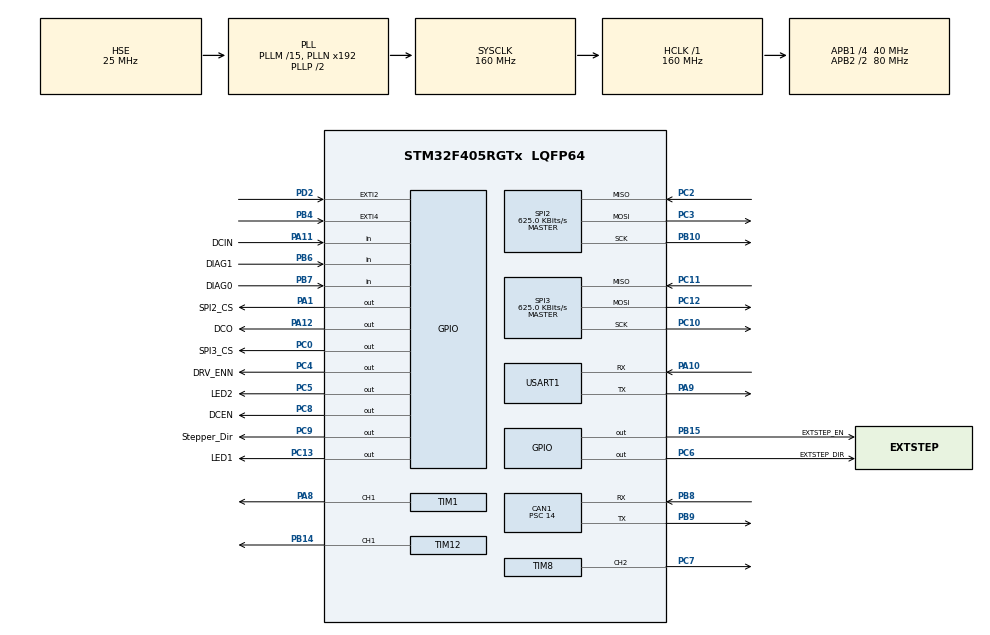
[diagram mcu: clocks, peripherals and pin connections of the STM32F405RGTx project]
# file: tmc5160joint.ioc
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CAN1.BS1=CAN_BS1_10TQ
CAN1.CalculateTimeQuantum=350.0
CAN1.Prescaler=14
Dma.Request0=USART1_RX
Dma.Request1=USART1_TX
Dma.USART1_RX.0.Direction=DMA_PERIPH_TO_MEMORY
Dma.USART1_RX.0.FIFOMode=DMA_FIFOMODE_DISABLE
Dma.USART1_RX.0.Instance=DMA2_Stream2
Dma.USART1_RX.0.MemDataAlignment=DMA_MDATAALIGN_BYTE
Dma.USART1_RX.0.MemInc=DMA_MINC_ENABLE
Dma.USART1_RX.0.Mode=DMA_CIRCULAR
Dma.USART1_RX.0.PeriphDataAlignment=DMA_PDATAALIGN_BYTE
Dma.USART1_RX.0.PeriphInc=DMA_PINC_DISABLE
Dma.USART1_RX.0.Priority=DMA_PRIORITY_LOW
Dma.USART1_TX.1.Direction=DMA_MEMORY_TO_PERIPH
Dma.USART1_TX.1.FIFOMode=DMA_FIFOMODE_DISABLE
Dma.USART1_TX.1.Instance=DMA2_Stream7
Dma.USART1_TX.1.MemDataAlignment=DMA_MDATAALIGN_BYTE
Dma.USART1_TX.1.MemInc=DMA_MINC_ENABLE
Dma.USART1_TX.1.Mode=DMA_NORMAL
Dma.USART1_TX.1.PeriphDataAlignment=DMA_PDATAALIGN_BYTE
Dma.USART1_TX.1.PeriphInc=DMA_PINC_DISABLE
Dma.USART1_TX.1.Priority=DMA_PRIORITY_LOW
FREERTOS.Tasks01=defaultTask,24,256,DefaultTaskMain,Default,NULL,Dynamic,NULL,NULL;ledTask,8,128,LedTaskMain,Default,NULL,Dynamic,NULL,NULL;encoderTask,8,512,EncoderTaskMain,Default,NULL,Dynamic,NULL,NULL;uartTask,8,128,UITaskMain,Default,NULL,Dynamic,NULL,NULL;canTask,8,512,CanCommTaskMain,Default,NULL,Dynamic,NULL,NULL
Mcu.Family=STM32F4
Mcu.Name=STM32F405RGTx
Mcu.Package=LQFP64
NVIC.CAN1_RX0_IRQn=true\:0\:0\:false\:false\:true\:false\:true\:true
NVIC.CAN1_RX1_IRQn=true\:0\:0\:false\:false\:true\:false\:true\:true
NVIC.CAN1_SCE_IRQn=true\:0\:0\:false\:false\:true\:false\:true\:true
NVIC.CAN1_TX_IRQn=true\:0\:0\:false\:false\:true\:false\:true\:true
NVIC.DMA2_Stream2_IRQn=true\:0\:0\:false\:false\:true\:true\:false\:true
NVIC.DMA2_Stream7_IRQn=true\:0\:0\:false\:false\:true\:true\:false\:true
NVIC.EXTI2_IRQn=true\:0\:0\:false\:false\:true\:false\:true\:true
NVIC.PriorityGroup=NVIC_PRIORITYGROUP_4
NVIC.TIM1_CC_IRQn=true\:0\:0\:false\:false\:true\:false\:true\:true
NVIC.TIM1_UP_TIM10_IRQn=true\:0\:0\:false\:false\:true\:false\:true\:true
NVIC.TIM2_IRQn=true\:0\:0\:false\:false\:true\:false\:true\:true
NVIC.TIM5_IRQn=true\:0\:0\:false\:false\:true\:false\:true\:true
NVIC.TIM8_UP_TIM13_IRQn=true\:0\:0\:false\:false\:true\:false\:false\:true
NVIC.TimeBase=TIM8_UP_TIM13_IRQn
NVIC.TimeBaseIP=TIM13
NVIC.USART1_IRQn=true\:0\:0\:false\:false\:true\:false\:true\:true
PA1.GPIO_Label=SPI2_CS
PA1.GPIO_Speed=GPIO_SPEED_FREQ_HIGH
PA1.Signal=GPIO_Output
PA10.Mode=Asynchronous
PA10.Signal=USART1_RX
PA11.GPIO_Label=DCIN
PA11.Signal=GPIO_Input
PA12.GPIO_Label=DCO
PA12.Signal=GPIO_Output
PA13.Mode=Serial_Wire
PA13.Signal=SYS_JTMS-SWDIO
PA14.Mode=Serial_Wire
PA14.Signal=SYS_JTCK-SWCLK
PA8.Signal=S_TIM1_CH1
PA9.Mode=Asynchronous
PA9.Signal=USART1_TX
PB10.Mode=Full_Duplex_Master
PB10.Signal=SPI2_SCK
PB14.Signal=S_TIM12_CH1
PB15.GPIO_Label=EXTSTEP_EN
PB15.Signal=GPIO_Output
PB4.Signal=GPXTI4
PB6.GPIO_Label=DIAG1
PB6.Signal=GPIO_Input
PB7.GPIO_Label=DIAG0
PB7.Signal=GPIO_Input
PB8.Mode=Master
PB8.Signal=CAN1_RX
PB9.Mode=Master
PB9.Signal=CAN1_TX
PC0.GPIO_Label=SPI3_CS
PC0.GPIO_PuPd=GPIO_PULLUP
PC0.GPIO_Speed=GPIO_SPEED_FREQ_HIGH
PC0.Signal=GPIO_Output
PC10.Mode=Full_Duplex_Master
PC10.Signal=SPI3_SCK
PC11.Mode=Full_Duplex_Master
PC11.Signal=SPI3_MISO
PC12.Mode=Full_Duplex_Master
PC12.Signal=SPI3_MOSI
PC13-ANTI_TAMP.GPIO_Label=LED1
PC13-ANTI_TAMP.Signal=GPIO_Output
PC14-OSC32_IN.Mode=LSE-External-Oscillator
PC14-OSC32_IN.Signal=RCC_OSC32_IN
PC15-OSC32_OUT.Mode=LSE-External-Oscillator
PC15-OSC32_OUT.Signal=RCC_OSC32_OUT
PC2.Mode=Full_Duplex_Master
PC2.Signal=SPI2_MISO
PC3.Mode=Full_Duplex_Master
PC3.Signal=SPI2_MOSI
PC4.GPIO_Label=DRV_ENN
PC4.Signal=GPIO_Output
PC5.GPIO_Label=LED2
PC5.Signal=GPIO_Output
PC6.GPIO_Label=EXTSTEP_DIR
PC6.Signal=GPIO_Output
PC7.Signal=S_TIM8_CH2
PC8.GPIO_Label=DCEN
PC8.Signal=GPIO_Output
PC9.GPIO_Label=Stepper_Dir
PC9.Signal=GPIO_Output
PD2.Signal=GPXTI2
PH0-OSC_IN.Mode=HSE-External-Oscillator
PH0-OSC_IN.Signal=RCC_OSC_IN
PH1-OSC_OUT.Mode=HSE-External-Oscillator
PH1-OSC_OUT.Signal=RCC_OSC_OUT
ProjectManager.HeapSize=0x200
ProjectManager.StackSize=0x400
ProjectManager.TargetToolchain=STM32CubeIDE
RCC.48MHZClocksFreq_Value=80000000
RCC.AHBFreq_Value=160000000
RCC.APB1CLKDivider=RCC_HCLK_DIV4
RCC.APB1Freq_Value=40000000
RCC.APB1TimFreq_Value=80000000
RCC.APB2CLKDivider=RCC_HCLK_DIV2
RCC.APB2Freq_Value=80000000
RCC.APB2TimFreq_Value=160000000
RCC.CortexFreq_Value=160000000
RCC.HCLKFreq_Value=160000000
RCC.HSE_VALUE=25000000
RCC.HSI_VALUE=16000000
RCC.PLLM=15
RCC.PLLSourceVirtual=RCC_PLLSOURCE_HSE
RCC.SYSCLKFreq_VALUE=160000000
RCC.SYSCLKSource=RCC_SYSCLKSOURCE_PLLCLK
RCC.VCOOutputFreq_Value=320000000
SH.S_TIM12_CH1.0=TIM12_CH1,PWM Generation1 CH1
SH.S_TIM1_CH1.0=TIM1_CH1,PWM Generation1 CH1
SH.S_TIM8_CH2.0=TIM8_CH2,PWM Generation2 CH2
SPI2.BaudRatePrescaler=SPI_BAUDRATEPRESCALER_64
SPI2.CalculateBaudRate=625.0 KBits/s
SPI2.Direction=SPI_DIRECTION_2LINES
SPI2.Mode=SPI_MODE_MASTER
SPI2.VirtualType=VM_MASTER
SPI3.BaudRatePrescaler=SPI_BAUDRATEPRESCALER_64
SPI3.CLKPhase=SPI_PHASE_2EDGE
SPI3.CalculateBaudRate=625.0 KBits/s
SPI3.DataSize=SPI_DATASIZE_16BIT
SPI3.Direction=SPI_DIRECTION_2LINES
SPI3.Mode=SPI_MODE_MASTER
SPI3.VirtualType=VM_MASTER
TIM1.Channel-PWM\ Generation1\ CH1=TIM_CHANNEL_1
TIM1.Period=499
TIM1.Prescaler=83
TIM1.Pulse-PWM\ Generation1\ CH1=250
TIM1.TIM_MasterOutputTrigger=TIM_TRGO_UPDATE
TIM12.Channel-PWM\ Generation1\ CH1=TIM_CHANNEL_1
TIM12.Period=5
TIM12.Prescaler=6
TIM12.Pulse-PWM\ Generation1\ CH1=3
TIM2.Channel-Output\ Compare1\ No\ Output=TIM_CHANNEL_1
TIM2.Period=999
TIM2.Prescaler=999
TIM2.TIM_MasterOutputTrigger=TIM_TRGO_UPDATE
TIM5.Channel-Output\ Compare1\ No\ Output=TIM_CHANNEL_1
TIM5.Period=1999
TIM5.Prescaler=83
TIM5.TIM_MasterOutputTrigger=TIM_TRGO_UPDATE
TIM8.AutoReloadPreload=TIM_AUTORELOAD_PRELOAD_ENABLE
TIM8.Channel-PWM\ Generation2\ CH2=TIM_CHANNEL_2
TIM8.Period=6
TIM8.Prescaler=1
TIM8.Pulse-PWM\ Generation2\ CH2=3
TIM8.TIM_MasterOutputTrigger=TIM_TRGO_UPDATE
TIM8.TIM_MasterSlaveMode=TIM_MASTERSLAVEMODE_DISABLE
USART1.VirtualMode=VM_ASYNC
VP_FREERTOS_VS_CMSIS_V2.Mode=CMSIS_V2
VP_SYS_VS_tim13.Mode=TIM13
VP_TIM2_VS_no_output1.Mode=Output Compare1 No Output
VP_TIM5_VS_no_output1.Mode=Output Compare1 No Output
board=custom

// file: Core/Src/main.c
/* USER CODE BEGIN Header */
/**
  ******************************************************************************
  * @file           : main.c
  * @brief          : Main program body
  ******************************************************************************
  * @attention
  *
  * <h2><center>&copy; Copyright (c) 2021 STMicroelectronics.
  * All rights reserved.</center></h2>
  *
  * This software component is licensed by ST under BSD 3-Clause license,
  * the "License"; You may not use this file except in compliance with the
  * License. You may obtain a copy of the License at:
  *                        opensource.org/licenses/BSD-3-Clause
  *
  ******************************************************************************
  */
/* USER CODE END Header */
#include "main.h"
#include "cmsis_os.h"
#include "can.h"
#include "dma.h"
#include "spi.h"
#include "tim.h"
#include "usart.h"
#include "gpio.h"
#include "posprofile.h"
/* USER CODE BEGIN Includes */
#include "nmotion.h"
/* USER CODE END Includes */

/* USER CODE BEGIN PV */
uint8_t g_GPIOInitFinished = 0;
/* USER CODE END PV */

void SystemClock_Config(void);
void MX_FREERTOS_Init(void);
/* USER CODE BEGIN PFP */
extern void initialise_monitor_handles(void);
/* USER CODE END PFP */

int main(void)
{
  /* USER CODE BEGIN 1 */
  initialise_monitor_handles();
  /* USER CODE END 1 */

  /* MCU Configuration--------------------------------------------------------*/

  /* Reset of all peripherals, Initializes the Flash interface and the Systick. */
  HAL_Init();

  /* Configure the system clock */
  SystemClock_Config();

  /* Initialize all configured peripherals */
  MX_GPIO_Init();
  MX_DMA_Init();
  MX_CAN1_Init();
  MX_SPI3_Init();
  MX_TIM1_Init();
  MX_TIM2_Init();
  MX_TIM5_Init();
  MX_USART1_UART_Init();
  MX_SPI2_Init();
  MX_TIM8_Init();
  MX_TIM12_Init();
  /* USER CODE BEGIN 2 */
  g_GPIOInitFinished = 1;
  /* USER CODE END 2 */

  PosProfile_Initialize();

  /*
  PosProfile_Start(30.26, -3.745f, 0, 125.0F, 125.0f, 125.0F, 0.004);
  for (int i = 0; i < 200; i++){
      PosProfile_Step(100);
  }
  PosProfile_Start(37.84, -31.625f, 0, 125.0F, 125.0f, 125.0F, 0.004);
  for (int i = 0; i < 2000; i++){
      PosProfile_Step(100);
      printf("cmd vel: %ld\n", (int32_t)roundf(rtY.CmdVel * 200.0F));
  }
	*/
/*
  uint32_t st = HAL_GetTick();

  for (int i = 0; i < 10; i++){
	  PosProfile_Start(-100, 0, 0, 140, 120, 120, 0.004);
	  //PosProfile_Start(-300, -40, 0, 140, 120, 120, 0.004);

  	  for (int i = 0; i < 800; i++){
  		  PosProfile_Step(100);
  		  //printf("cmd vel: %ld\n", (int32_t)roundf(rtY.CmdVel * 200.0F));
  	  }
  }

  printf("Exhaust time: %ld\n", st);
*/
  /* Init scheduler */
  osKernelInitialize();  /* Call init function for freertos objects (in freertos.c) */
  MX_FREERTOS_Init();
  /* Start scheduler */
  osKernelStart();

  /* We should never get here as control is now taken by the scheduler */
  /* Infinite loop */
  while (1)
  {

  }
}

void SystemClock_Config(void)
{
  RCC_OscInitTypeDef RCC_OscInitStruct = {0};
  RCC_ClkInitTypeDef RCC_ClkInitStruct = {0};

  /** Configure the main internal regulator output voltage
  */
  __HAL_RCC_PWR_CLK_ENABLE();
  __HAL_PWR_VOLTAGESCALING_CONFIG(PWR_REGULATOR_VOLTAGE_SCALE1);
  /** Initializes the RCC Oscillators according to the specified parameters
  * in the RCC_OscInitTypeDef structure.
  */
  RCC_OscInitStruct.OscillatorType = RCC_OSCILLATORTYPE_HSE;
  RCC_OscInitStruct.HSEState = RCC_HSE_ON;
  RCC_OscInitStruct.PLL.PLLState = RCC_PLL_ON;
  RCC_OscInitStruct.PLL.PLLSource = RCC_PLLSOURCE_HSE;
  RCC_OscInitStruct.PLL.PLLM = 15;
  RCC_OscInitStruct.PLL.PLLN = 192;
  RCC_OscInitStruct.PLL.PLLP = RCC_PLLP_DIV2;
  RCC_OscInitStruct.PLL.PLLQ = 4;
  if (HAL_RCC_OscConfig(&RCC_OscInitStruct) != HAL_OK)
  {
    Error_Handler();
  }
  /** Initializes the CPU, AHB and APB buses clocks
  */
  RCC_ClkInitStruct.ClockType = RCC_CLOCKTYPE_HCLK|RCC_CLOCKTYPE_SYSCLK
                              |RCC_CLOCKTYPE_PCLK1|RCC_CLOCKTYPE_PCLK2;
  RCC_ClkInitStruct.SYSCLKSource = RCC_SYSCLKSOURCE_PLLCLK;
  RCC_ClkInitStruct.AHBCLKDivider = RCC_SYSCLK_DIV1;
  RCC_ClkInitStruct.APB1CLKDivider = RCC_HCLK_DIV4;
  RCC_ClkInitStruct.APB2CLKDivider = RCC_HCLK_DIV2;

  if (HAL_RCC_ClockConfig(&RCC_ClkInitStruct, FLASH_LATENCY_5) != HAL_OK)
  {
    Error_Handler();
  }
}

void HAL_TIM_PeriodElapsedCallback(TIM_HandleTypeDef *htim)
{
  if (htim->Instance == TIM13) {
    HAL_IncTick();
  }

  /* USER CODE BEGIN Callback 1 */
  if (htim->Instance == TIM5){
	  MT_process_v3(4);
  }
  /* USER CODE END Callback 1 */
}

void Error_Handler(void)
{
}

/************************ (C) COPYRIGHT STMicroelectronics *****END OF FILE****/
